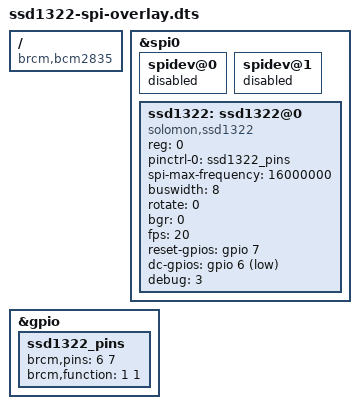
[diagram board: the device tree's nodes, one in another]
/*
    Device Tree overlay for SSD1322 SPI controller.

    Based on overlay for Sainsmart 3.2" display by Alexander Lehmann
    https://github.com/Flugtiger

    Default pins:
    DC#    = GPIO6
    RESET# = GPIO7

*/
 
/dts-v1/;
/plugin/;
 
/ {
    compatible = "brcm,bcm2835", "brcm,bcm2708", "brcm,bcm2709";
 
    fragment@0
    {
        target = <&spi0>;
        __overlay__
        {
            status = "okay";
  
            spidev@0
            {
                status = "disabled";
            };
 
            spidev@1
            {
                status = "disabled";
            };
        };
    };
 
    fragment@1
    {
        target = <&gpio>;
        __overlay__
        {
            ssd1322_pins: ssd1322_pins
            {
                brcm,pins = <6 7>;
                brcm,function = <1 1>;
            };
        };
    };
 
    fragment@2
    {
        target = <&spi0>;
        __overlay__
        {
            #address-cells = <1>;
            #size-cells = <0>;
 
            ssd1322: ssd1322@0
            {
                compatible = "solomon,ssd1322";
                reg = <0>;
 
                pinctrl-names = "default";
                pinctrl-0 = <&ssd1322_pins>;

                spi-max-frequency = <16000000>;
                buswidth = <8>;
                rotate = <0>;
                bgr = <0>;
                fps = <20>;

                reset-gpios = <&gpio 7 0>;
                dc-gpios = <&gpio 6 1>;
                debug = <3>;
            };
 
        };
    };

    __overrides__
    {
        speed     = <&ssd1322>,"spi-max-frequency:0";
        rotate    = <&ssd1322>,"rotate:0";
        bgr       = <&ssd1322>,"bgr:0";
        fps       = <&ssd1322>,"fps:0";
        resetgpio = <&ssd1322>,"reset-gpios:4",
                    <&ssd1322_pins>, "brcm,pins:1";
        dcgpio    = <&ssd1322>,"dc-gpios:4",
                    <&ssd1322_pins>, "brcm,pins:2";
        debug     = <&ssd1322>,"debug:0";
    };
};
 
